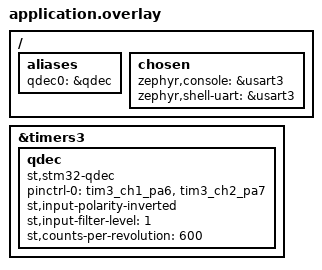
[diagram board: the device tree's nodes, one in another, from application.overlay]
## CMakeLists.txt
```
cmake_minimum_required(VERSION 3.20.0)
unset(CONF_FILE CACHE)

set(BOARD_FLASH_RUNNER jlink)

list(APPEND CONF_FILE ${CMAKE_CURRENT_SOURCE_DIR}/prj.conf)
list(APPEND DTC_OVERLAY_FILE ${CMAKE_CURRENT_SOURCE_DIR}/application.overlay)

if(DEFINED TEST)
  list(APPEND CONF_FILE ${CMAKE_CURRENT_SOURCE_DIR}/test.conf)
endif()

# !!! IMPORTANT !!! ###################################################################################################
# The find_package(Zephyr REQUIRED HINTS $ENV{ZEPHYR_BASE}) command, which is part of the Zephyr application 
# boilerplate code, essentially loads the Zephyr build system. When it's executed, it sets up various configuration 
# options, including CONF_FILE. If CONF_FILE is not stored in the cache before find_package is called, the value 
# will be overwritten with the Zephyr defaults.
# By using set(CONF_FILE ${CONF_FILE} CACHE INTERNAL "conf_file") before the find_package command, we're storing 
# the CONF_FILE configuration in the CMake cache. This ensures that the configuration is retained when find_package 
# is called.
set(CONF_FILE ${CONF_FILE} CACHE INTERNAL "conf_file")
find_package(Zephyr REQUIRED HINTS $ENV{ZEPHYR_BASE})
project(nucleo_f767zi)

target_sources(app PRIVATE
  src/main.c
)

zephyr_library_include_directories(.)
```

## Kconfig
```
menu "VelocityEstimator configuration"

source "Kconfig.zephyr"

rsource "src/Kconfig"

endmenu
```

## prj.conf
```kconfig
CONFIG_HEAP_MEM_POOL_SIZE=4096
CONFIG_DEBUG=y
CONFIG_MAIN_STACK_SIZE=2048

# Config logging subsystem
CONFIG_LOG=y
CONFIG_LOG_PRINTK=n
CONFIG_LOG_MODE_DEFERRED=y
CONFIG_LOG_PROCESS_THREAD=y
CONFIG_LOG_PROCESS_THREAD_SLEEP_MS=20

# Config shell
CONFIG_SHELL=y
CONFIG_SHELL_BACKEND_SERIAL=y
CONFIG_SHELL_PROMPT_UART="$ "

# Config networking
CONFIG_NETWORKING=y
CONFIG_NET_SOCKETS=y
CONFIG_NET_SHELL=y
CONFIG_NET_LOG=y
CONFIG_NET_SOCKETS_POSIX_NAMES=y
CONFIG_NET_IPV4=y
CONFIG_NET_IPV6=n
CONFIG_NET_CONFIG_SETTINGS=y
CONFIG_NET_CONFIG_MY_IPV4_ADDR="192.168.1.55"
CONFIG_NET_CONFIG_MY_IPV4_GW="192.168.1.1"
CONFIG_NET_TCP=y
CONFIG_NET_BUF_DATA_SIZE=128
# CONFIG_NET_CONFIG_PEER_IPV4_ADDR="192.0.2.2"

# Config C lib
CONFIG_NEWLIB_LIBC=y
CONFIG_NEWLIB_LIBC_FLOAT_PRINTF=y
```

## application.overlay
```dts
/ {
    aliases {
        qdec0 = &qdec;
    };

    chosen {
        zephyr,console = &usart3;
        zephyr,shell-uart = &usart3;
    };
};

&timers3 {
    status = "okay";

    qdec: qdec {
        status = "okay";
        compatible = "st,stm32-qdec";
        pinctrl-0 = <&tim3_ch1_pa6 &tim3_ch2_pa7>;
        pinctrl-names = "default";
        st,input-polarity-inverted;
        st,input-filter-level = <1>;
        st,counts-per-revolution = <600>;
    };
};
```

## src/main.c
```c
/*=================================================================================================
 *                _____           _                 ______    _          _ _
 *               / ____|         | |               |  ____|  | |        (_) |
 *              | (___  _   _ ___| |_ ___ _ __ ___ | |__ __ _| |__  _ __ _| | _____ _ __
 *               \___ \| | | / __| __/ _ \ '_ ` _ \|  __/ _` | '_ \| '__| | |/ / _ \ '_ \
 *               ____) | |_| \__ \ ||  __/ | | | | | | | (_| | |_) | |  | |   <  __/ | | |
 *              |_____/ \__, |___/\__\___|_| |_| |_|_|  \__,_|_.__/|_|  |_|_|\_\___|_| |_|
 *                       __/ |
 *                      |___/
 * Description:
 *     In header file
 *
 * SPDX-License-Identifier: Apache-2.0
 * Copyright (c) 2023 Albin Hjalmas
 * contact: albin@systemfabriken.tech
 *=================================================================================================
 * INCLUDES
 *===============================================================================================*/
#include <stdio.h>
#include <string.h>
#include <stdlib.h>
#include <zephyr/kernel.h>
#include <zephyr/logging/log.h>
#include <zephyr/device.h>
#include <zephyr/net/socket.h>
#include <zephyr/net/net_mgmt.h>

LOG_MODULE_REGISTER(main, LOG_LEVEL_DBG);

#define SERVER_PORT 12345
static char buf[CONFIG_NET_BUF_DATA_SIZE];

static void net_mgmt_cb(struct net_mgmt_event_callback *cb, uint32_t mgmt_event,
			struct net_if *iface)
{
	if (mgmt_event == NET_EVENT_IF_DOWN) {
		LOG_INF("Network interface went down");
		// Handle the interface down event
	} else if (mgmt_event == NET_EVENT_IF_UP) {
		LOG_INF("Network interface went up");
		// Handle the interface up event
	}
}

/*=================================================================================================
 * PROGRAM ENTRY POINT
 ================================================================================================*/
int main(void)
{
	int server_fd, client_fd;
	struct sockaddr_in server_addr, client_addr;
	socklen_t client_addr_len = sizeof(client_addr);
	int received;
	static struct net_mgmt_event_callback net_mgmt_cb_data;

	net_mgmt_init_event_callback(&net_mgmt_cb_data, net_mgmt_cb,
				     NET_EVENT_IF_DOWN | NET_EVENT_IF_UP);
	net_mgmt_add_event_callback(&net_mgmt_cb_data);

	// Initialize server address structure
	memset(&server_addr, 0, sizeof(server_addr));
	server_addr.sin_family = AF_INET;
	server_addr.sin_port = htons(SERVER_PORT);
	server_addr.sin_addr.s_addr = htonl(INADDR_ANY);

	// Create socket
	LOG_INF("Creating socket...");
	server_fd = socket(AF_INET, SOCK_STREAM, IPPROTO_TCP);
	if (server_fd < 0) {
		LOG_ERR("Could not create socket (%i) %s", errno, strerror(errno));
		return EXIT_FAILURE;
	}

	// Bind socket
	LOG_INF("Binding socket...");
	if (bind(server_fd, (struct sockaddr *)&server_addr, sizeof(server_addr)) < 0) {
		LOG_ERR("Could not bind socket (%i) %s", errno, strerror(errno));
		close(server_fd);
		return EXIT_FAILURE;
	}

	// Listen for incoming connections
	LOG_INF("Listening on socket...");
	if (listen(server_fd, 5) < 0) {
		LOG_ERR("Could not listen on socket (%i) %s", errno, strerror(errno));
		close(server_fd);
		return EXIT_FAILURE;
	}

	LOG_INF("Server listening on port %d", SERVER_PORT);

	// Accept incoming connections
	while (1) {
		LOG_INF("Waiting for a client connection...");
		client_fd = accept(server_fd, (struct sockaddr *)&client_addr, &client_addr_len);
		if (client_fd < 0) {
			LOG_ERR("Could not accept connection");
			continue;
		}

		LOG_INF("Client connected");

		// Echo back data received
		do {
			received = recv(client_fd, buf, sizeof(buf), 0);
			LOG_INF("Received %d bytes", received);
			LOG_HEXDUMP_INF(buf, received, "Data received");
			if (received > 0) {
				send(client_fd, buf, received, 0);
			}
		} while (received > 0);

		close(client_fd);
		LOG_INF("Client disconnected");
	}

	// Cleanup
	close(server_fd);

	return EXIT_SUCCESS;
}

/*=================================================================================================
 * PRIVATE FUNCTION DEFINITIONS
 ================================================================================================*/
#ifdef CONFIG_ASSERT
extern void assert_post_action(const char *file, unsigned int line);
void assert_post_action(const char *file, unsigned int line)
{
	LOG_ERR("ASSERTION FAILED @ %s:%d", file, line);
}
#endif
```

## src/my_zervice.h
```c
/*=================================================================================================
 *                _____           _                 ______    _          _ _
 *               / ____|         | |               |  ____|  | |        (_) |
 *              | (___  _   _ ___| |_ ___ _ __ ___ | |__ __ _| |__  _ __ _| | _____ _ __
 *               \___ \| | | / __| __/ _ \ '_ ` _ \|  __/ _` | '_ \| '__| | |/ / _ \ '_ \
 *               ____) | |_| \__ \ ||  __/ | | | | | | | (_| | |_) | |  | |   <  __/ | | |
 *              |_____/ \__, |___/\__\___|_| |_| |_|_|  \__,_|_.__/|_|  |_|_|\_\___|_| |_|
 *                       __/ |
 *                      |___/
 *
 * SPDX-License-Identifier: Apache-2.0
 * Copyright (c) 2023 Systemfabriken AB
 * contact: albin@systemfabriken.tech
 *===============================================================================================*/
#ifndef _MY_ZERVICE_H_
#define _MY_ZERVICE_H_

/*=================================================================================================
 * INCLUDES
 *===============================================================================================*/
#include <zephyr/zerv/zerv.h>

/*=================================================================================================
 * PUBLIC MACROS
 *===============================================================================================*/

ZERV_CMD_REGISTER(my_zervice, echo, ZERV_CMD_PARAM(const char *message, size_t length),
		  ZERV_CMD_RETURN(const char *message, size_t length));
ZERV_CMD_REGISTER(my_zervice, sum, ZERV_CMD_PARAM(int a, int b), ZERV_CMD_RETURN(int sum));
ZERV_CMD_REGISTER(my_zervice, print_hello, EMPTY, EMPTY);

/*=================================================================================================
 * PUBLIC FUNCTION DECLARATIONS
 *===============================================================================================*/

#endif /* _MY_ZERVICE_H_ */
```
